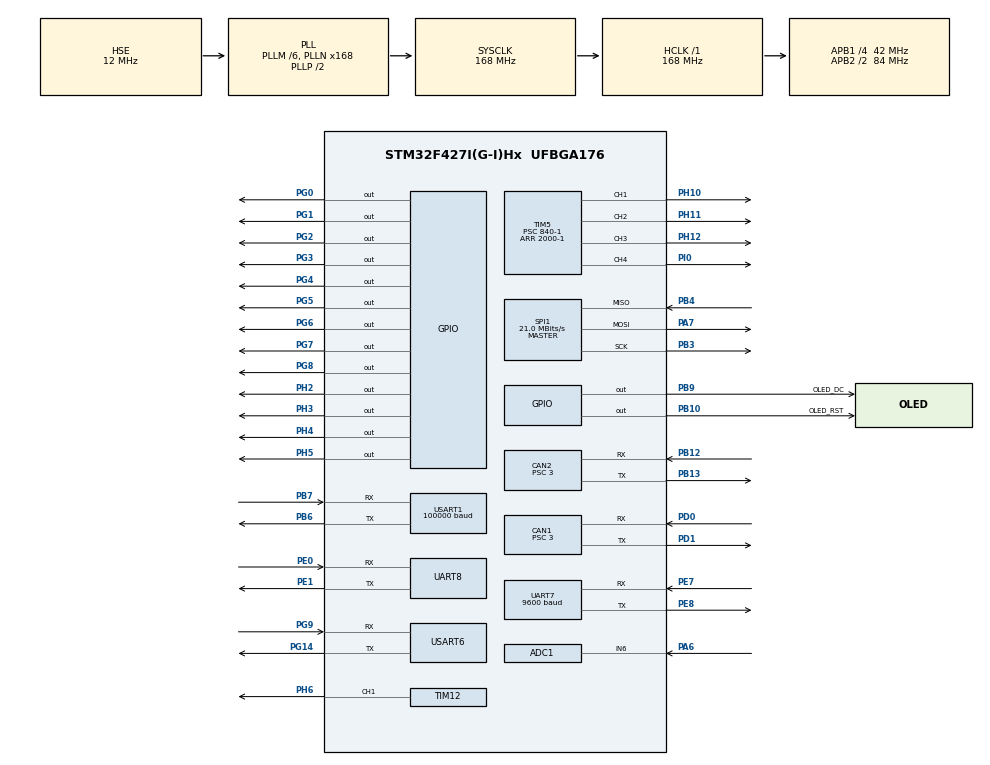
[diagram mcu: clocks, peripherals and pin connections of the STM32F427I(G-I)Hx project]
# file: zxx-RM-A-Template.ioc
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ADC1.Channel-0\#ChannelRegularConversion=ADC_CHANNEL_6
ADC1.NbrOfConversionFlag=1
ADC1.Rank-0\#ChannelRegularConversion=1
ADC1.SamplingTime-0\#ChannelRegularConversion=ADC_SAMPLETIME_3CYCLES
ADC1.master=1
CAN1.BS1=CAN_BS1_10TQ
CAN1.BS2=CAN_BS2_3TQ
CAN1.CalculateBaudRate=1000000
CAN1.CalculateTimeBit=1000
CAN1.CalculateTimeQuantum=71.42857142857143
CAN1.Prescaler=3
CAN2.BS1=CAN_BS1_10TQ
CAN2.BS2=CAN_BS2_3TQ
CAN2.CalculateBaudRate=1000000
CAN2.CalculateTimeBit=1000
CAN2.CalculateTimeQuantum=71.42857142857143
CAN2.Prescaler=3
Dma.ADC1.0.Direction=DMA_PERIPH_TO_MEMORY
Dma.ADC1.0.FIFOMode=DMA_FIFOMODE_DISABLE
Dma.ADC1.0.Instance=DMA2_Stream0
Dma.ADC1.0.MemDataAlignment=DMA_MDATAALIGN_WORD
Dma.ADC1.0.MemInc=DMA_MINC_ENABLE
Dma.ADC1.0.Mode=DMA_CIRCULAR
Dma.ADC1.0.PeriphDataAlignment=DMA_PDATAALIGN_WORD
Dma.ADC1.0.PeriphInc=DMA_PINC_DISABLE
Dma.ADC1.0.Priority=DMA_PRIORITY_LOW
Dma.Request0=ADC1
Dma.Request1=UART7_RX
Dma.Request2=UART8_RX
Dma.Request3=USART1_RX
Dma.UART7_RX.1.Direction=DMA_PERIPH_TO_MEMORY
Dma.UART7_RX.1.FIFOMode=DMA_FIFOMODE_DISABLE
Dma.UART7_RX.1.Instance=DMA1_Stream3
Dma.UART7_RX.1.MemDataAlignment=DMA_MDATAALIGN_BYTE
Dma.UART7_RX.1.MemInc=DMA_MINC_ENABLE
Dma.UART7_RX.1.Mode=DMA_CIRCULAR
Dma.UART7_RX.1.PeriphDataAlignment=DMA_PDATAALIGN_BYTE
Dma.UART7_RX.1.PeriphInc=DMA_PINC_DISABLE
Dma.UART7_RX.1.Priority=DMA_PRIORITY_VERY_HIGH
Dma.UART8_RX.2.Direction=DMA_PERIPH_TO_MEMORY
Dma.UART8_RX.2.FIFOMode=DMA_FIFOMODE_DISABLE
Dma.UART8_RX.2.Instance=DMA1_Stream6
Dma.UART8_RX.2.MemDataAlignment=DMA_MDATAALIGN_BYTE
Dma.UART8_RX.2.MemInc=DMA_MINC_ENABLE
Dma.UART8_RX.2.Mode=DMA_NORMAL
Dma.UART8_RX.2.PeriphDataAlignment=DMA_PDATAALIGN_BYTE
Dma.UART8_RX.2.PeriphInc=DMA_PINC_DISABLE
Dma.UART8_RX.2.Priority=DMA_PRIORITY_VERY_HIGH
Dma.USART1_RX.3.Direction=DMA_PERIPH_TO_MEMORY
Dma.USART1_RX.3.FIFOMode=DMA_FIFOMODE_DISABLE
Dma.USART1_RX.3.Instance=DMA2_Stream2
Dma.USART1_RX.3.MemDataAlignment=DMA_MDATAALIGN_BYTE
Dma.USART1_RX.3.MemInc=DMA_MINC_ENABLE
Dma.USART1_RX.3.Mode=DMA_CIRCULAR
Dma.USART1_RX.3.PeriphDataAlignment=DMA_PDATAALIGN_BYTE
Dma.USART1_RX.3.PeriphInc=DMA_PINC_DISABLE
Dma.USART1_RX.3.Priority=DMA_PRIORITY_LOW
FREERTOS.Tasks01=defaultTask,0,128,StartDefaultTask,Default,NULL,Dynamic,NULL,NULL;DJI_Motor_Task,-2,128,DJI_Motor_Entry,As weak,NULL,Dynamic,NULL,NULL;OLED_Task,2,128,OLED_Task_Entry,As weak,NULL,Dynamic,NULL,NULL;RC_Task,2,128,RC_Task_Entry,As weak,NULL,Dynamic,NULL,NULL;Chassis_Task,1,128,Chassis_Task_Entry,As weak,NULL,Dynamic,NULL,NULL
Mcu.Family=STM32F4
Mcu.Name=STM32F427I(G-I)Hx
Mcu.Package=UFBGA176
NVIC.CAN1_RX0_IRQn=true\:5\:0\:false\:false\:true\:true\:true\:true
NVIC.CAN1_TX_IRQn=true\:5\:0\:false\:false\:true\:true\:true\:true
NVIC.CAN2_RX0_IRQn=true\:5\:0\:false\:false\:true\:true\:true\:true
NVIC.CAN2_TX_IRQn=true\:5\:0\:false\:false\:true\:true\:true\:true
NVIC.DMA1_Stream3_IRQn=true\:5\:0\:false\:false\:true\:true\:false\:true
NVIC.DMA1_Stream6_IRQn=true\:5\:0\:false\:false\:true\:true\:false\:true
NVIC.DMA2_Stream0_IRQn=true\:5\:0\:false\:false\:true\:true\:false\:true
NVIC.DMA2_Stream2_IRQn=true\:5\:0\:false\:false\:true\:true\:false\:true
NVIC.PriorityGroup=NVIC_PRIORITYGROUP_4
NVIC.TIM1_UP_TIM10_IRQn=true\:15\:0\:false\:false\:true\:false\:false\:true
NVIC.TimeBase=TIM1_UP_TIM10_IRQn
NVIC.TimeBaseIP=TIM1
NVIC.UART7_IRQn=true\:5\:0\:false\:false\:true\:true\:true\:true
NVIC.UART8_IRQn=true\:5\:0\:false\:false\:true\:true\:true\:true
NVIC.USART1_IRQn=true\:5\:0\:false\:false\:true\:true\:true\:true
NVIC.USART6_IRQn=true\:5\:0\:false\:false\:true\:true\:true\:true
PA6.Signal=ADCx_IN6
PA7.Mode=Full_Duplex_Master
PA7.Signal=SPI1_MOSI
PB10.GPIO_Label=OLED_RST
PB10.Signal=GPIO_Output
PB12.Mode=CAN_Activate
PB12.Signal=CAN2_RX
PB13.Mode=CAN_Activate
PB13.Signal=CAN2_TX
PB3.Mode=Full_Duplex_Master
PB3.Signal=SPI1_SCK
PB4.Mode=Full_Duplex_Master
PB4.Signal=SPI1_MISO
PB6.Mode=Asynchronous
PB6.Signal=USART1_TX
PB7.Mode=Asynchronous
PB7.Signal=USART1_RX
PB9.GPIO_Label=OLED_DC
PB9.Signal=GPIO_Output
PD0.Mode=CAN_Activate
PD0.Signal=CAN1_RX
PD1.Mode=CAN_Activate
PD1.Signal=CAN1_TX
PE0.Mode=Asynchronous
PE0.Signal=UART8_RX
PE1.Mode=Asynchronous
PE1.Signal=UART8_TX
PE7.Mode=Asynchronous
PE7.Signal=UART7_RX
PE8.Mode=Asynchronous
PE8.Signal=UART7_TX
PG0.Signal=GPIO_Output
PG1.Signal=GPIO_Output
PG14.Mode=Asynchronous
PG14.Signal=USART6_TX
PG2.Signal=GPIO_Output
PG3.Signal=GPIO_Output
PG4.Signal=GPIO_Output
PG5.Signal=GPIO_Output
PG6.Signal=GPIO_Output
PG7.Signal=GPIO_Output
PG8.Signal=GPIO_Output
PG9.Mode=Asynchronous
PG9.Signal=USART6_RX
PH0/OSC_IN.Mode=HSE-External-Oscillator
PH0/OSC_IN.Signal=RCC_OSC_IN
PH1/OSC_OUT.Mode=HSE-External-Oscillator
PH1/OSC_OUT.Signal=RCC_OSC_OUT
PH10.Signal=S_TIM5_CH1
PH11.Signal=S_TIM5_CH2
PH12.Signal=S_TIM5_CH3
PH2.Signal=GPIO_Output
PH3.Signal=GPIO_Output
PH4.Signal=GPIO_Output
PH5.Signal=GPIO_Output
PH6.Signal=S_TIM12_CH1
PI0.Signal=S_TIM5_CH4
ProjectManager.HeapSize=0x200
ProjectManager.StackSize=0x400
ProjectManager.TargetToolchain=SW4STM32
RCC.48MHZClocksFreq_Value=84000000
RCC.AHBFreq_Value=168000000
RCC.APB1CLKDivider=RCC_HCLK_DIV4
RCC.APB1Freq_Value=42000000
RCC.APB1TimFreq_Value=84000000
RCC.APB2CLKDivider=RCC_HCLK_DIV2
RCC.APB2Freq_Value=84000000
RCC.APB2TimFreq_Value=168000000
RCC.CortexFreq_Value=168000000
RCC.HCLKFreq_Value=168000000
RCC.HSE_VALUE=12000000
RCC.HSI_VALUE=16000000
RCC.LSE_VALUE=32768
RCC.PLLM=6
RCC.PLLN=168
RCC.PLLSourceVirtual=RCC_PLLSOURCE_HSE
RCC.SYSCLKFreq_VALUE=168000000
RCC.SYSCLKSource=RCC_SYSCLKSOURCE_PLLCLK
RCC.VCOOutputFreq_Value=336000000
SH.ADCx_IN6.0=ADC1_IN6,IN6
SH.S_TIM12_CH1.0=TIM12_CH1,PWM Generation1 CH1
SH.S_TIM5_CH1.0=TIM5_CH1,PWM Generation1 CH1
SH.S_TIM5_CH2.0=TIM5_CH2,PWM Generation2 CH2
SH.S_TIM5_CH3.0=TIM5_CH3,PWM Generation3 CH3
SH.S_TIM5_CH4.0=TIM5_CH4,PWM Generation4 CH4
SPI1.BaudRatePrescaler=SPI_BAUDRATEPRESCALER_4
SPI1.CalculateBaudRate=21.0 MBits/s
SPI1.Direction=SPI_DIRECTION_2LINES
SPI1.Mode=SPI_MODE_MASTER
SPI1.VirtualType=VM_MASTER
TIM12.Channel-PWM\ Generation1\ CH1=TIM_CHANNEL_1
TIM12.Period=500-1
TIM12.Prescaler=84-1
TIM2.Period=100-1
TIM2.Prescaler=840-1
TIM5.Channel-PWM\ Generation1\ CH1=TIM_CHANNEL_1
TIM5.Channel-PWM\ Generation2\ CH2=TIM_CHANNEL_2
TIM5.Channel-PWM\ Generation3\ CH3=TIM_CHANNEL_3
TIM5.Channel-PWM\ Generation4\ CH4=TIM_CHANNEL_4
TIM5.Period=2000-1
TIM5.Prescaler=840-1
UART7.BaudRate=9600
UART7.VirtualMode=Asynchronous
UART8.VirtualMode=Asynchronous
USART1.BaudRate=100000
USART1.Parity=PARITY_EVEN
USART1.StopBits=STOPBITS_2
USART1.VirtualMode=VM_ASYNC
USART1.WordLength=WORDLENGTH_9B
USART6.VirtualMode=VM_ASYNC
VP_FREERTOS_VS_CMSIS_V1.Mode=CMSIS_V1
VP_SYS_VS_tim1.Mode=TIM1
VP_TIM2_VS_ClockSourceINT.Mode=Internal
VP_TIM5_VS_ClockSourceINT.Mode=Internal
board=custom

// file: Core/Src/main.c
/* USER CODE BEGIN Header */
/**
  ******************************************************************************
  * @file           : main.c
  * @brief          : Main program body
  ******************************************************************************
  * @attention
  *
  * Copyright (c) 2022 STMicroelectronics.
  * All rights reserved.
  *
  * This software is licensed under terms that can be found in the LICENSE file
  * in the root directory of this software component.
  * If no LICENSE file comes with this software, it is provided AS-IS.
  *
  ******************************************************************************
  */
/* USER CODE END Header */
#include "main.h"
#include "cmsis_os.h"
#include "adc.h"
#include "can.h"
#include "dma.h"
#include "spi.h"
#include "tim.h"
#include "usart.h"
#include "gpio.h"

/* USER CODE BEGIN Includes */
#include "board_config.h"
#include "bsp_led.h"
#include "bsp_can.h"
#include "bsp_usart.h"
/* USER CODE END Includes */

void SystemClock_Config(void);
void MX_FREERTOS_Init(void);

int main(void)
{

  /* MCU Configuration--------------------------------------------------------*/

  /* Reset of all peripherals, Initializes the Flash interface and the Systick. */
  HAL_Init();

  /* Configure the system clock */
  SystemClock_Config();

  /* Initialize all configured peripherals */
  MX_GPIO_Init();
  MX_DMA_Init();
  MX_ADC1_Init();
  MX_CAN1_Init();
  MX_SPI1_Init();
  MX_TIM2_Init();
  MX_TIM5_Init();
  MX_TIM12_Init();
  MX_UART7_Init();
  MX_UART8_Init();
  MX_USART6_UART_Init();
  MX_USART1_UART_Init();
  MX_CAN2_Init();
  /* USER CODE BEGIN 2 */
  /** Usart IRQ Init **/
  Usart_IdleIRQ_Init(&huart1);
  Usart_IdleIRQ_Init(&huart7);
  Usart_IdleIRQ_Init(&huart8);
  /** Board LED Init **/
  #ifndef BOARD_LED_INIT_ON
  Led_All_Off();
  #endif

  /** Can Filter Init **/
  CAN_Filter_Init();

  /* USER CODE END 2 */

  /* Call init function for freertos objects (in freertos.c) */
  MX_FREERTOS_Init();
  /* Start scheduler */
  osKernelStart();

  /* We should never get here as control is now taken by the scheduler */
  /* Infinite loop */
    while (1)
    {

    }
}

void SystemClock_Config(void)
{
  RCC_OscInitTypeDef RCC_OscInitStruct = {0};
  RCC_ClkInitTypeDef RCC_ClkInitStruct = {0};

  /** Configure the main internal regulator output voltage
  */
  __HAL_RCC_PWR_CLK_ENABLE();
  __HAL_PWR_VOLTAGESCALING_CONFIG(PWR_REGULATOR_VOLTAGE_SCALE1);
  /** Initializes the RCC Oscillators according to the specified parameters
  * in the RCC_OscInitTypeDef structure.
  */
  RCC_OscInitStruct.OscillatorType = RCC_OSCILLATORTYPE_HSE;
  RCC_OscInitStruct.HSEState = RCC_HSE_ON;
  RCC_OscInitStruct.PLL.PLLState = RCC_PLL_ON;
  RCC_OscInitStruct.PLL.PLLSource = RCC_PLLSOURCE_HSE;
  RCC_OscInitStruct.PLL.PLLM = 6;
  RCC_OscInitStruct.PLL.PLLN = 168;
  RCC_OscInitStruct.PLL.PLLP = RCC_PLLP_DIV2;
  RCC_OscInitStruct.PLL.PLLQ = 4;
  if (HAL_RCC_OscConfig(&RCC_OscInitStruct) != HAL_OK)
  {
    Error_Handler();
  }
  /** Initializes the CPU, AHB and APB buses clocks
  */
  RCC_ClkInitStruct.ClockType = RCC_CLOCKTYPE_HCLK|RCC_CLOCKTYPE_SYSCLK
                              |RCC_CLOCKTYPE_PCLK1|RCC_CLOCKTYPE_PCLK2;
  RCC_ClkInitStruct.SYSCLKSource = RCC_SYSCLKSOURCE_PLLCLK;
  RCC_ClkInitStruct.AHBCLKDivider = RCC_SYSCLK_DIV1;
  RCC_ClkInitStruct.APB1CLKDivider = RCC_HCLK_DIV4;
  RCC_ClkInitStruct.APB2CLKDivider = RCC_HCLK_DIV2;

  if (HAL_RCC_ClockConfig(&RCC_ClkInitStruct, FLASH_LATENCY_5) != HAL_OK)
  {
    Error_Handler();
  }
}

void HAL_TIM_PeriodElapsedCallback(TIM_HandleTypeDef *htim)
{
  if (htim->Instance == TIM1) {
    HAL_IncTick();
  }
}

void Error_Handler(void)
{
    __disable_irq();
    while (1)
    {
    }
}

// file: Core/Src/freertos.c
/* USER CODE BEGIN Header */
/**
  ******************************************************************************
  * File Name          : freertos.c
  * Description        : Code for freertos applications
  ******************************************************************************
  * @attention
  *
  * Copyright (c) 2022 STMicroelectronics.
  * All rights reserved.
  *
  * This software is licensed under terms that can be found in the LICENSE file
  * in the root directory of this software component.
  * If no LICENSE file comes with this software, it is provided AS-IS.
  *
  ******************************************************************************
  */
/* USER CODE END Header */

#include "FreeRTOS.h"
#include "task.h"
#include "main.h"
#include "cmsis_os.h"

osThreadId defaultTaskHandle;
osThreadId DJI_Motor_TaskHandle;
osThreadId OLED_TaskHandle;
osThreadId RC_TaskHandle;
osThreadId Chassis_TaskHandle;

void StartDefaultTask(void const * argument);
void DJI_Motor_Entry(void const * argument);
void OLED_Task_Entry(void const * argument);
void RC_Task_Entry(void const * argument);
void Chassis_Task_Entry(void const * argument);

void MX_FREERTOS_Init(void); /* (MISRA C 2004 rule 8.1) */

/* GetIdleTaskMemory prototype (linked to static allocation support) */
void vApplicationGetIdleTaskMemory( StaticTask_t **ppxIdleTaskTCBBuffer, StackType_t **ppxIdleTaskStackBuffer, uint32_t *pulIdleTaskStackSize );

/* USER CODE BEGIN GET_IDLE_TASK_MEMORY */
static StaticTask_t xIdleTaskTCBBuffer;
static StackType_t xIdleStack[configMINIMAL_STACK_SIZE];

void vApplicationGetIdleTaskMemory( StaticTask_t **ppxIdleTaskTCBBuffer, StackType_t **ppxIdleTaskStackBuffer, uint32_t *pulIdleTaskStackSize )
{
  *ppxIdleTaskTCBBuffer = &xIdleTaskTCBBuffer;
  *ppxIdleTaskStackBuffer = &xIdleStack[0];
  *pulIdleTaskStackSize = configMINIMAL_STACK_SIZE;
  /* place for user code */
}
/* USER CODE END GET_IDLE_TASK_MEMORY */

void MX_FREERTOS_Init(void) {

  /* Create the thread(s) */
  /* definition and creation of defaultTask */
  osThreadDef(defaultTask, StartDefaultTask, osPriorityNormal, 0, 128);
  defaultTaskHandle = osThreadCreate(osThread(defaultTask), NULL);

  /* definition and creation of DJI_Motor_Task */
  osThreadDef(DJI_Motor_Task, DJI_Motor_Entry, osPriorityLow, 0, 128);
  DJI_Motor_TaskHandle = osThreadCreate(osThread(DJI_Motor_Task), NULL);

  /* definition and creation of OLED_Task */
  osThreadDef(OLED_Task, OLED_Task_Entry, osPriorityHigh, 0, 128);
  OLED_TaskHandle = osThreadCreate(osThread(OLED_Task), NULL);

  /* definition and creation of RC_Task */
  osThreadDef(RC_Task, RC_Task_Entry, osPriorityHigh, 0, 128);
  RC_TaskHandle = osThreadCreate(osThread(RC_Task), NULL);

  /* definition and creation of Chassis_Task */
  osThreadDef(Chassis_Task, Chassis_Task_Entry, osPriorityAboveNormal, 0, 128);
  Chassis_TaskHandle = osThreadCreate(osThread(Chassis_Task), NULL);

}

void StartDefaultTask(void const * argument)
{
  for(;;)
  {
    osDelay(1);
  }
}

__weak void DJI_Motor_Entry(void const * argument)
{
  for(;;)
  {
    osDelay(1);
  }
}

__weak void OLED_Task_Entry(void const * argument)
{
  for(;;)
  {
    osDelay(1);
  }
}

__weak void RC_Task_Entry(void const * argument)
{
  for(;;)
  {
    osDelay(1);
  }
}

__weak void Chassis_Task_Entry(void const * argument)
{
  for(;;)
  {
    osDelay(1);
  }
}
